# TIMER2_L4_PER1Interconnect register map
Vendor: Texas Instruments
Peripheral module from a debugger description file (folder DRA75x_DRA74x).
Registers are 32-bit, access per field, reset 0x0 unless marked. A register's access mark holds for its fields unless they carry their own. Offsets are as the file gives them; lines under a group give offsets from that group; [hi:lo] are bit positions; {n}, {i} and the like mark numbered series; 'fields as' and 'values as' point back to an identical list; <NAME> marks a mode.

## TIMER2_L4_PER1Interconnect
0x00 TIDR ro reset not defined — This read-only register contains the revision number of the module. A write to this register has no effect. This register is used by software to track features, bugs, and compatibility.
  [31:0] REVISION — IP Revision
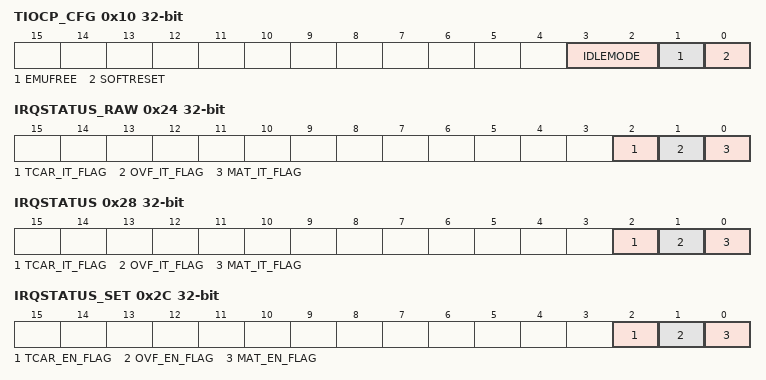
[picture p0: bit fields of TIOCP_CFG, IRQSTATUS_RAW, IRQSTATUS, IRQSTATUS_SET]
0x10 TIOCP_CFG — This register controls the various parameters of the L4 interface.
  [3:2] IDLEMODE rw — Power management, req/ack control
    0=Idle_Mode_0x0 (Force-idle mode: local target idle state follows (acknowledges) the system idle requests unconditionally, that is, regardless of the IP module internal requirements. Back-up mode, for debug only.); 1=Idle_Mode_0x1 (No-idle mode: local target never enters idle state. Back-up mode, for debug only.); 2=Idle_Mode_0x2 (Smart-idle mode: local target idle state eventually follows (acknowledges) the system idle requests, depending on the IP module internal requirements. IP module should not generate (IRQ- or DMA-request-related) wake-up events.); 3=Idle_Mode_0x3 (Smart-idle wake-up-capable mode: local target idle state eventually follows (acknowledges) the system idle requests, depending on the IP module internal requirements. IP module may generate (IRQ- or DMA-request-related) wake-up events when in IDLE state. Mode is relevant only if the appropriate IP moduleswake-up output(s) is (are) implemented.)
  [1] EMUFREE rw — Emulation mode
    0=timer_frozen (The timer is frozen in emulation mode (PINSUSPENDN signal active).); 1=timer_free (The timer runs free, regardless of PINSUSPENDN value.)
  [0] SOFTRESET rw — Software reset
    0=SoftReset_Value_0 (Read 0: reset done, no pending action Write 0: No action); 1=SoftReset_Value_1 (Read 1: initiate software reset Write 1: Reset ongoing)
0x20 IRQ_EOI — Software End-Of-Interrupt: Allows the generation of further pulses on the interrupt line, if a new interrupt event is pending, when using the pulsed output. Unused when using the level interrupt line (depending on module integration).
  [0] LINE_NUMBER rw — Write the number of the interrupt line to apply a SW EOI to it. Note that there is only a single line (i.e. number 0). Read: Read always returns 0 Write 0: SW EOI on interrupt line Write 1: No action
0x24 IRQSTATUS_RAW — Component interrupt-request status. Check the corresponding secondary status register. Raw status is set even if event is not enabled. Write 1 to set the (raw) status, mostly for debug.
  [2] TCAR_IT_FLAG rw — IRQ status for capture Read 0: No event pending Write 0: No action Read 1: IRQ event pending Write 1: Trigger IRQ event by software.
  [1] OVF_IT_FLAG rw — IRQ status for overflow Read 0: No event pending Write 0: No action Read 1: IRQ event pending Write 1: Trigger IRQ event by software.
  [0] MAT_IT_FLAG rw — IRQ status for match Read 0: No event pending Write 0: No action Read 1: IRQ event pending Write 1: Trigger IRQ event by software.
0x28 IRQSTATUS — Component interrupt-request status. Check the corresponding secondary status register. Enabled status is not set unless event is enabled. Write 1 to clear the status after interrupt has been serviced (raw status gets cleared, that is, even if not enabled).
  [2] TCAR_IT_FLAG rw — IRQ status for capture Read 0: No event pending Write 0: No action Read 1: IRQ event pending Write 1: Clear any pending event.
  [1] OVF_IT_FLAG rw — IRQ status for overflow Read 0: No event pending Write 0: No action Read 1: IRQ event pending Write 1: Clear any pending event.
  [0] MAT_IT_FLAG rw — IRQ status for match Read 0: No event pending Write 0: No action Read 1: IRQ event pending Write 1: Clear any pending event.
0x2C IRQSTATUS_SET — Component interrupt-request enable. Write 1 to set (enable interrupt). Readout equal to corresponding _CLR register.
  [2] TCAR_EN_FLAG rw — IRQ enable for compare Read 0: IRQ event is disabled. Write 0: No action Read 1: IRQ event is enabled Write 1: Set IRQ enable.
  [1] OVF_EN_FLAG rw — IRQ enable for overflow Read 0: IRQ event is disabled. Write 0: No action Read 1: IRQ event is enabled. Write 1: Set IRQ enable.
  [0] MAT_EN_FLAG rw — IRQ enable for match Read 0: IRQ event is disabled. Write 0: No action Read 1: IRQ event is enabled. Write 1: Set IRQ enable.
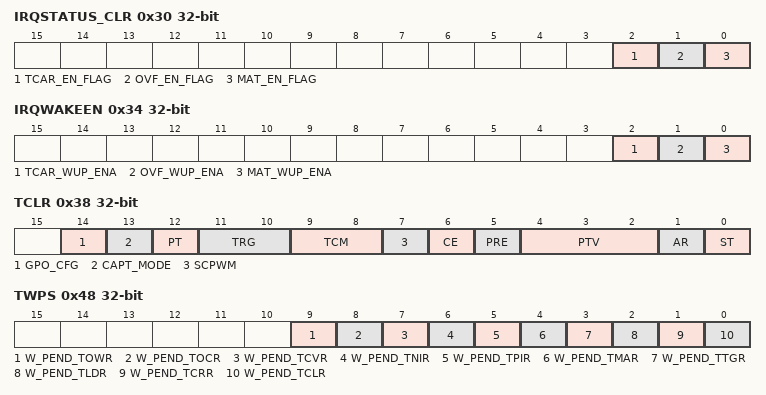
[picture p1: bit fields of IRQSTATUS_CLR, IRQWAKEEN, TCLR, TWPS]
0x30 IRQSTATUS_CLR — Component interrupt-request enable. Write 1 to clear (disable interrupt). Readout equal to corresponding _SET register.
  [2] TCAR_EN_FLAG rw — IRQ enable for compare Read 0: IRQ event is disabled. Write 0: No action Read 1: IRQ event is enabled. Write 1: Clear IRQ enable.
  [1] OVF_EN_FLAG rw — IRQ enable for overflow Read 0: IRQ event is disabled. Write 0: No action Read 1: IRQ event is enabled. Write 1: Clear IRQ enable.
  [0] MAT_EN_FLAG rw — IRQ enable for match Read 0: IRQ event is disabled. Write 0: No action Read 1: IRQ event is enabled. Write 1: Clear IRQ enable.
0x34 IRQWAKEEN — Wake-up-enabled events taking place when module is idle should generate an asynchronous wake-up.
  [2] TCAR_WUP_ENA rw — Wake-up generation for compare
    0=TCAR_WUP_ENA_Value_0 (Wake-up disabled); 1=TCAR_WUP_ENA_Value_1 (Wake-up enabled)
  [1] OVF_WUP_ENA rw — Wake-up generation for overflow
    0=OVF_WUP_ENA_Value_0 (Wake-up disabled); 1=OVF_WUP_ENA_Value_1 (Wake-up enabled)
  [0] MAT_WUP_ENA rw — Wake-up generation for match
    0=MAT_WUP_ENA_VALUE_0 (Wake-up disabled); 1=MAT_WUP_ENA_VALUE_1 (Wake-up enabled)
0x38 TCLR — This register controls optional features specific to the timer functionality.
  [14] GPO_CFG rw — General-purpose output - this register directly drives the PO_GPOCFG output. For specific use of the GPO_CFG bit, see, GP Timer External System Interface.
    0=PO_GPOCFG drives 0; 1=PO_GPOCFG drives 1
  [13] CAPT_MODE rw — Capture mode select bit (first/second)
    0=First_capt (Single capture: Capture the first enabled capture event in.); 1=Sec_capt (Capture on second event: Capture the second enabled capture event in TCAR1 and the second enabled capture event in.)
  [12] PT rw — Pulse or toggle mode on TIMERi_PWM_out output pin
    0=Pulse modulation; 1=Toggle modulation
  [11:10] TRG rw — Trigger output mode on TIMERi_PWM_out output pin
    0=no_trg (No trigger); 1=ovf_trg (Trigger on overflow.); 2=ovf_mat_trg (Trigger on overflow and match.)
  [9:8] TCM rw — Transition capture mode on TIMERi_EVENT_CAPTURE input pin (When the TCM field passed from (00) to any other combination, the TCAR_IT_FLAG and the edge detection logic are cleared.)
    0=no_edge (No capture); 1=rise_edge (Capture on rising edges of TIMERi_EVENT_CAPTURE pin); 2=fall_edge (Capture on falling edges of TIMERi_EVENT_CAPTURE pin); 3=both_edges (Capture on both edges of TIMERi_EVENT_CAPTURE pin)
  [7] SCPWM rw — Pulse width modulation output pin default setting This bit must be set or clear while the timer is stopped or the trigger is off.
    0=def_low (Clear the TIMERi_PWM_out output pin and select positive pulse for pulse mode.); 1=def_high (Set the TIMERi_PWM_out output pin and select negative pulse for pulse mode.)
  [6] CE rw — Compare enable
    0=dsb_cmp (Compare mode is disable.); 1=enb_cmp (Compare mode is enable.)
  [5] PRE rw — Prescaler enable
    0=no_prescal (The TIMER clock input pin clocks the counter.); 1=prescal_on (The divided input pin clocks the counter.)
  [4:2] PTV rw — Prescale clock timer value The timer counter is prescaled with the value 2. Example: PTV = 3, counter increases value (if started) after 16 functional clock periods.
  [1] AR rw — Autoreload mode
    0=One shot timer; 1=Autoreload timer
  [0] ST rw — Start/stop timer control
    0=cnt_stop (Stop timer: Only the counter is frozen. If one-shot mode selected (AR =0), this bit is automatically reset by internal logic when the counter is overflowed.); 1=cnt_start (Start timer)
0x3C TCRR rw — This register holds the value of the internal counter.
  [31:0] TIMER_COUNTER — Value of TIMER counter
0x40 TLDR rw — This register holds the timer load value.
  [31:0] LOAD_VALUE — Timer counter value loaded on overflow in autoreload mode or onTTGR write access. LOAD_VALUE must be different than the timer overflow value (0xFFFF FFFF).
0x44 TTGR access not given reset 0xFFFFFFFF — The read value of this register is always 0xFFFF FFFF.
  [31:0] TTGR_VALUE — Writing to theTTGR register causes the TCRR to be loaded from TLDR and the prescaler counter to be cleared. Reload is done regardless of the AR field value of the TCLR register. (access RW Rreturns1s)
0x48 TWPS ro — This register contains the write posting bits for all writable functional registers.
  [9] W_PEND_TOWR — Write pending for theTOWR register
    1=Write_pending; 0=No_write_pending
  [8] W_PEND_TOCR — Write pending for theTOCR register
    1=Write_pending; 0=No_write_pending
  [7] W_PEND_TCVR — Write pending for theTCVR register
    1=Write_pending; 0=No_write_pending
  [6] W_PEND_TNIR — Write pending for theTNIR register
    1=W_PEND_TNIR_1_r (Negative increment register write pending); 0=W_PEND_TNIR_0_r (No negative increment register write pending)
  [5] W_PEND_TPIR — Write pending for theTPIR register
    1=W_PEND_TPIR_1_r (Positive increment register write pending); 0=W_PEND_TPIR_0_r (No positive increment register write pending)
  [4] W_PEND_TMAR — When equal to 1, a write is pending to theTMAR register.
  [3] W_PEND_TTGR — When equal to 1, a write is pending to theTTGR register.
  [2] W_PEND_TLDR — When equal to 1, a write is pending to theTLDR register.
  [1] W_PEND_TCRR — When equal to 1, a write is pending to theTCRR register.
  [0] W_PEND_TCLR — When equal to 1, a write is pending to theTCLR register.
0x4C TMAR rw — The compare logic consists of a 32-bit-wide, read/write data register and logic to compare counter.
  [31:0] COMPARE_VALUE — Value to be compared to the timer counter
0x50 TCAR1 ro — This register holds the first captured value of the counter register.
  [31:0] CAPTURE_VALUE1 — First timer counter value captured on an external event trigger
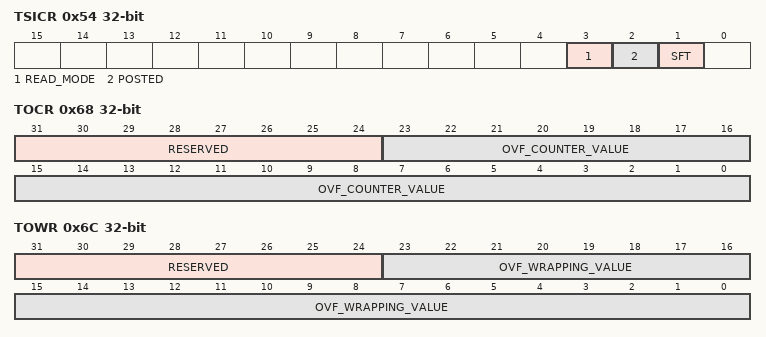
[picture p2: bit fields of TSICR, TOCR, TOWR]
0x54 TSICR (reset mask 0xFFFFFFFB) — Timer synchronous interface control register
  [3] READ_MODE rw — Select posted/non-posted mode for read operation:NOTE: When the module is configured in posted mode (POSTED = '1'), this bit is not used. . NOTE: For GP TIMER1, TIMER2 and TIMER10 this bit is write only. .
    0=(POSTED_0 (When the module is configured in non-posted mode (POSTED = '0'), the read operation is executed as read posted.); 1=(POSTED_1 (When the module is configured in non-posted mode (POSTED = '0'), the read operation is executed as read non-posted.)
  [2] POSTED rw — Posted mode selection
    0=POSTED_Value_0 (Posted mode inactive: Delay the command accept output signal.); 1=POSTED_Value_1 (Posted mode active)
  [1] SFT rw — This bit resets all the functional part of the module.
    0=Software reset is disabled; 1=Software reset is enabled
0x58 TCAR2 ro — This register holds the second captured value of the counter register.
  [31:0] CAPTURE_VALUE2 — Second timer counter value captured on an external event trigger
0x5C TPIR rw — This register is used for 1-ms tick generation. The register holds the value of the positive increment. The value of this register is added to the value of to determine whether next value loaded in is the subperiod value or the overperiod value.
  [31:0] POSITIVE_INC_VALUE — Value of the positive increment
0x60 TNIR rw — This register is used for 1-ms tick generation. The register holds the value of the negative increment. The value of this register is added to the value of the to determine whether next value loaded in is the subperiod value or the overperiod value.
  [31:0] NEGATIVE_INV_VALUE — Value of the negative increment
0x64 TCVR rw — This register is used for 1-ms tick generation. The register determines whether next value loaded in is the subperiod value or the overperiod value.
  [31:0] COUNTER_VALUE — Value of CVR counter
0x68 TOCR — This register is used to mask the tick interrupt for a selected number of ticks.
  [31:24] RESERVED ro — Reads return 0.
  [23:0] OVF_COUNTER_VALUE rw — Number of overflow events
0x6C TOWR — This register holds the number of masked overflow interrupts.
  [31:24] RESERVED ro — Reads return 0.
  [23:0] OVF_WRAPPING_VALUE rw — Number of masked interrupts
